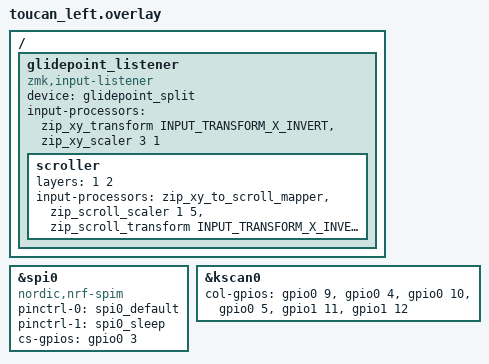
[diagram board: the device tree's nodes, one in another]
#include "toucan.dtsi"
#include "toucan_spi.dtsi"
#include <input/processors.dtsi>
#include <dt-bindings/zmk/input_transform.h>

nice_view_spi: &spi0 {
	compatible = "nordic,nrf-spim";
	pinctrl-0 = <&spi0_default>;
	pinctrl-1 = <&spi0_sleep>;
	pinctrl-names = "default", "sleep";
	cs-gpios = <&gpio0 3 GPIO_ACTIVE_HIGH>;
};

&kscan0 {
	col-gpios
		= <&gpio0 9 GPIO_ACTIVE_HIGH>
		, <&gpio0 4 GPIO_ACTIVE_HIGH>
		, <&gpio0 10 GPIO_ACTIVE_HIGH>
		, <&gpio0 5 GPIO_ACTIVE_HIGH>
		, <&gpio1 11 GPIO_ACTIVE_HIGH>
		, <&gpio1 12 GPIO_ACTIVE_HIGH>
		;
};

/* Central: receive split Cirque + scale / scroll on NAV|SYM. */
/ {
	glidepoint_listener: glidepoint_listener {
		compatible = "zmk,input-listener";
		device = <&glidepoint_split>;
		/* zip_xy_scaler is mul/div (not percent). 3/1 = 3×. */
		input-processors = <
			&zip_xy_transform INPUT_TRANSFORM_X_INVERT
			&zip_xy_scaler 3 1
		>;
		scroller {
			layers = <1 2>;
			input-processors = <
				&zip_xy_to_scroll_mapper
				&zip_scroll_scaler 1 5
				&zip_scroll_transform INPUT_TRANSFORM_X_INVERT
			>;
		};
	};
};
